# TMS320F280049 register map
Vendor: Texas Instruments; Series: C2000 F28004x; File version: 0.2.0-generated
Registers are 16-bit, read-write, reset 0x0 unless marked. A register's access mark holds for its fields unless they carry their own. Offsets are from the block's base; [hi:lo] are bit positions; {n}, {i} and the like mark numbered series; 'fields as' and 'values as' point back to an identical list.

## SYSPERIPHACREGS — PERIPH AC Registers
Base 0x000BAA00
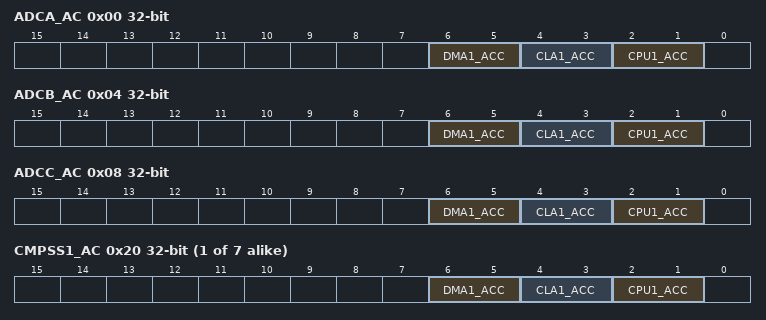
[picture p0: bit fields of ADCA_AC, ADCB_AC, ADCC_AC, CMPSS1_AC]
0x00 ADCA_AC 32-bit — ADCA Master Access Control Register
  [6:5] DMA1_ACC — DMA1 Access Conditions to Peripheral
  [4:3] CLA1_ACC — CLA1 Access Conditions to Peripheral
  [2:1] CPU1_ACC — CPU1 Access conditions to peripheral
0x04 ADCB_AC 32-bit — ADCB Master Access Control Register
  fields as ADCA_AC
0x08 ADCC_AC 32-bit — ADCC Master Access Control Register
  fields as ADCA_AC
{0x1C+4i} CMPSS{i}_AC 32-bit (i=1..7) — CMPSS{i} Master Access Control Register
  fields as ADCA_AC
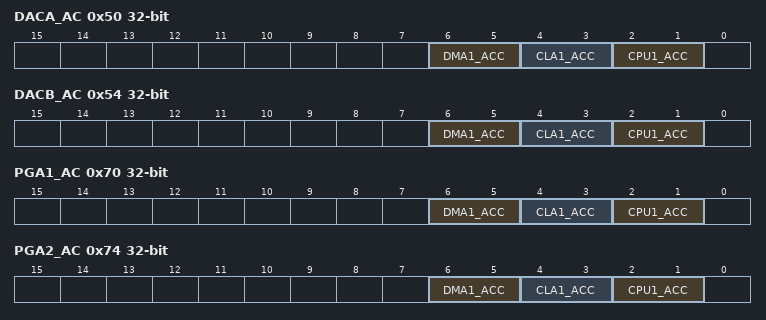
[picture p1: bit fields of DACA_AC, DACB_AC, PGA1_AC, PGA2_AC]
0x50 DACA_AC 32-bit — DACA Master Access Control Register
  fields as ADCA_AC
0x54 DACB_AC 32-bit — DACB Master Access Control Register
  fields as ADCA_AC
0x70 PGA1_AC 32-bit — PGAA Master Access Control Register
  fields as ADCA_AC
0x74 PGA2_AC 32-bit — PGAB Master Access Control Register
  fields as ADCA_AC
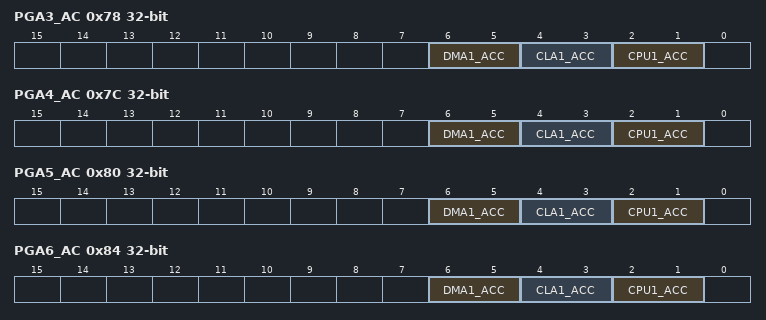
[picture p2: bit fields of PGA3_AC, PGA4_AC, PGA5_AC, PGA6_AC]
0x78 PGA3_AC 32-bit — PGAC Master Access Control Register
  fields as ADCA_AC
0x7C PGA4_AC 32-bit — PGAD Master Access Control Register
  fields as ADCA_AC
0x80 PGA5_AC 32-bit — PGAE Master Access Control Register
  fields as ADCA_AC
0x84 PGA6_AC 32-bit — PGAF Master Access Control Register
  fields as ADCA_AC
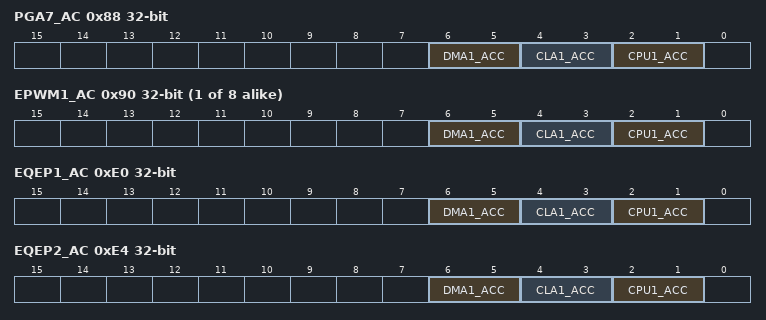
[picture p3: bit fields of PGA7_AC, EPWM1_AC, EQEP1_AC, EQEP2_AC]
0x88 PGA7_AC 32-bit — PGAG Master Access Control Register
  fields as ADCA_AC
{0x8C+4i} EPWM{i}_AC 32-bit (i=1..8) — EPWM{i} Master Access Control Register
  fields as ADCA_AC
0xE0 EQEP1_AC 32-bit — EQEP1 Master Access Control Register
  fields as ADCA_AC
0xE4 EQEP2_AC 32-bit — EQEP2 Master Access Control Register
  fields as ADCA_AC
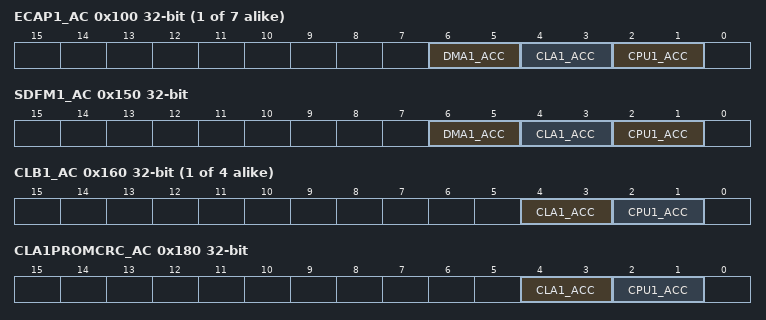
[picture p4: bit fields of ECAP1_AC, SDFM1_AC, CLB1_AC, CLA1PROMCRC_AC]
{0xFC+4i} ECAP{i}_AC 32-bit (i=1..7) — ECAP{i} Master Access Control Register
  fields as ADCA_AC
0x150 SDFM1_AC 32-bit — SDFM1 Master Access Control Register
  fields as ADCA_AC
{0x15C+4i} CLB{i}_AC 32-bit (i=1..4) — CLB{i} Master Access Control Register
  [4:3] CLA1_ACC — CLA1 Access Conditions to Peripheral
  [2:1] CPU1_ACC — CPU1 Access conditions to peripheral
0x180 CLA1PROMCRC_AC 32-bit — CLA1PROMCRC Master Access Control Register
  fields as CLB1_AC
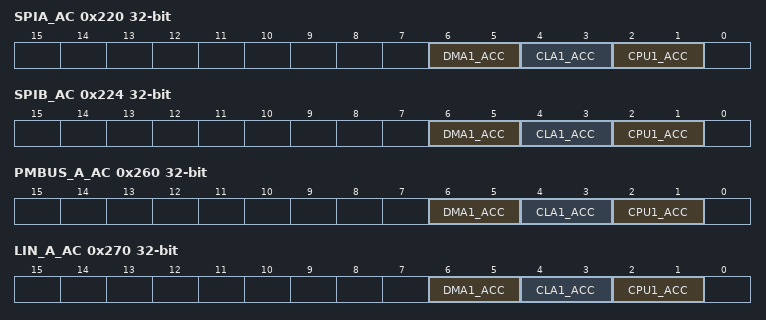
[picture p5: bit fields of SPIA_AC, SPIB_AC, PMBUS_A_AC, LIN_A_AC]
0x220 SPIA_AC 32-bit — SPIA Master Access Control Register
  fields as ADCA_AC
0x224 SPIB_AC 32-bit — SPIB Master Access Control Register
  fields as ADCA_AC
0x260 PMBUS_A_AC 32-bit — PMBUSA Master Access Control Register
  fields as ADCA_AC
0x270 LIN_A_AC 32-bit — LINA Master Access Control Register
  fields as ADCA_AC
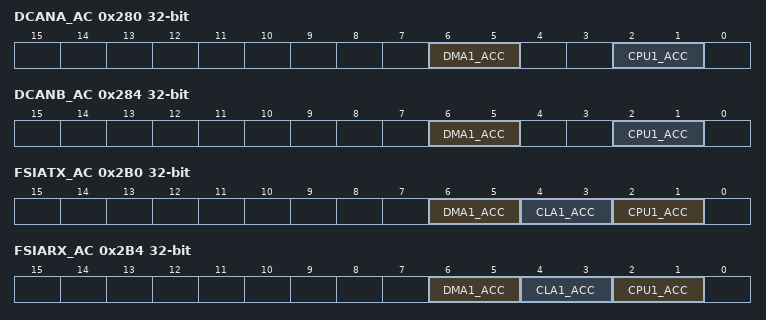
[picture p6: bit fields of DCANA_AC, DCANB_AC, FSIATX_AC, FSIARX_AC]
0x280 DCANA_AC 32-bit — DCANA Master Access Control Register
  [6:5] DMA1_ACC — DMA1 Access Conditions to Peripheral
  [2:1] CPU1_ACC — CPU1 Access conditions to peripheral
0x284 DCANB_AC 32-bit — DCANB Master Access Control Register
  fields as DCANA_AC
0x2B0 FSIATX_AC 32-bit — FSIA Master Access Control Register
  fields as ADCA_AC
0x2B4 FSIARX_AC 32-bit — FSIB Master Access Control Register
  fields as ADCA_AC
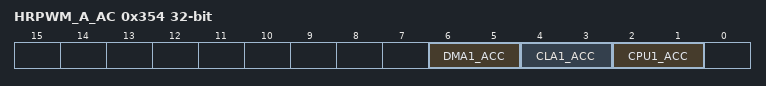
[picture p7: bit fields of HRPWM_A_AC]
0x354 HRPWM_A_AC 32-bit — HRPWM Master Access Control Register
  fields as ADCA_AC
0x3FC PERIPH_AC_LOCK 32-bit — Lock Register to stop Write access to peripheral Access register.
  [0] LOCK_AC_WR — Lock control for Access control registers write.

## ANALOGSUBSYSREGS — ANALOG SUBSYS Registers
Base 0x000BAE00
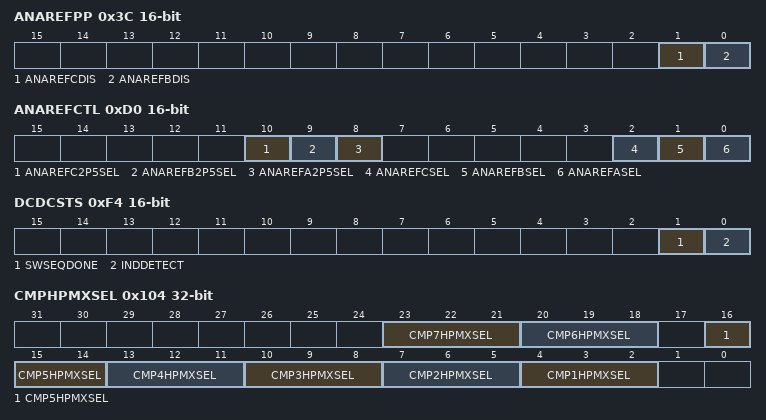
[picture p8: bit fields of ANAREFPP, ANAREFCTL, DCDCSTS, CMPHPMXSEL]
0x3C ANAREFPP — ADC Analog Reference Peripheral Properties register. The value of this register is populated during boot rom.
  [1] ANAREFCDIS — Disable ANAREFC
  [0] ANAREFBDIS — Disable ANAREFB
0xC0 TSNSCTL — Temperature Sensor Control Register
  [0] ENABLE — Temperature Sensor Enable
0xD0 ANAREFCTL — Analog Reference Control Register
  [10] ANAREFC2P5SEL — Analog Reference B Select
  [9] ANAREFB2P5SEL — Analog Reference B Select
  [8] ANAREFA2P5SEL — Analog Reference A Select
  [2] ANAREFCSEL — Analog Reference C Select
  [1] ANAREFBSEL — Analog Reference B Select
  [0] ANAREFASEL — Analog Reference A Select
0xE0 VMONCTL — Voltage Monitor Control Register
  [8] BORLVMONDIS — Disable BORL(ow) feature on VDDIO
0xF0 DCDCCTL 32-bit — DC-DC control register.
  [0] DCDCEN — DCDC Enable
0xF4 DCDCSTS — DC-DC status register.
  [1] SWSEQDONE — Switch sequence to DC-DC done.
  [0] INDDETECT — Inductor Detected
0x104 CMPHPMXSEL 32-bit — Bits to select one of the many sources on CopmHP inputs. Refer to Pimux diagram for details.
  [23:21] CMP7HPMXSEL — CMP7HPMXSEL bits
  [20:18] CMP6HPMXSEL — CMP6HPMXSEL bits
  [3n+1:3n-1] CMP{n}HPMXSEL (n=1..5) — CMP{n}HPMXSEL bits
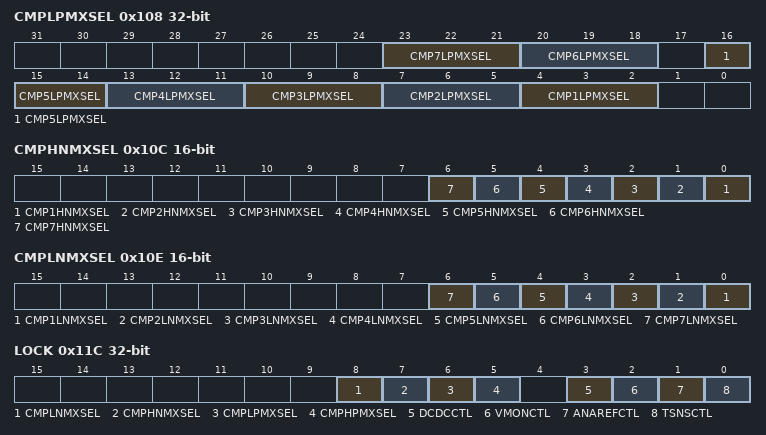
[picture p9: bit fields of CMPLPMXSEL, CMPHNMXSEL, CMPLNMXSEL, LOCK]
0x108 CMPLPMXSEL 32-bit — Bits to select one of the many sources on CopmLP inputs. Refer to Pimux diagram for details.
  [23:21] CMP7LPMXSEL — CMP7LPMXSEL bits
  [20:18] CMP6LPMXSEL — CMP6LPMXSEL bits
  [3n+1:3n-1] CMP{n}LPMXSEL (n=1..5) — CMP{n}LPMXSEL bits
0x10C CMPHNMXSEL — Bits to select one of the many sources on CopmHN inputs. Refer to Pimux diagram for details.
  [n-1] CMP{n}HNMXSEL (n=1..7) — CMP{n}HNMXSEL bits
0x10E CMPLNMXSEL — Bits to select one of the many sources on CopmLN inputs. Refer to Pimux diagram for details.
  [n-1] CMP{n}LNMXSEL (n=1..7) — CMP{n}LNMXSEL bits
0x11C LOCK 32-bit
  [8] CMPLNMXSEL — CMPLNMXSEL Register lock bit
  [7] CMPHNMXSEL — CMPHNMXSEL Register lock bit
  [6] CMPLPMXSEL — CMPLPMXSEL Register lock bit
  [5] CMPHPMXSEL — CMPHPMXSEL Register lock bit
  [3] DCDCCTL — DCDCCTL Register lock bit
  [2] VMONCTL — VMONCTL Register lock bit
  [1] ANAREFCTL — ANAREFCTL Register lock bit
  [0] TSNSCTL — TSNSCTL Register lock bit
